AUTOSAR XML (schema 4-0-3)
package /ComponentTypes
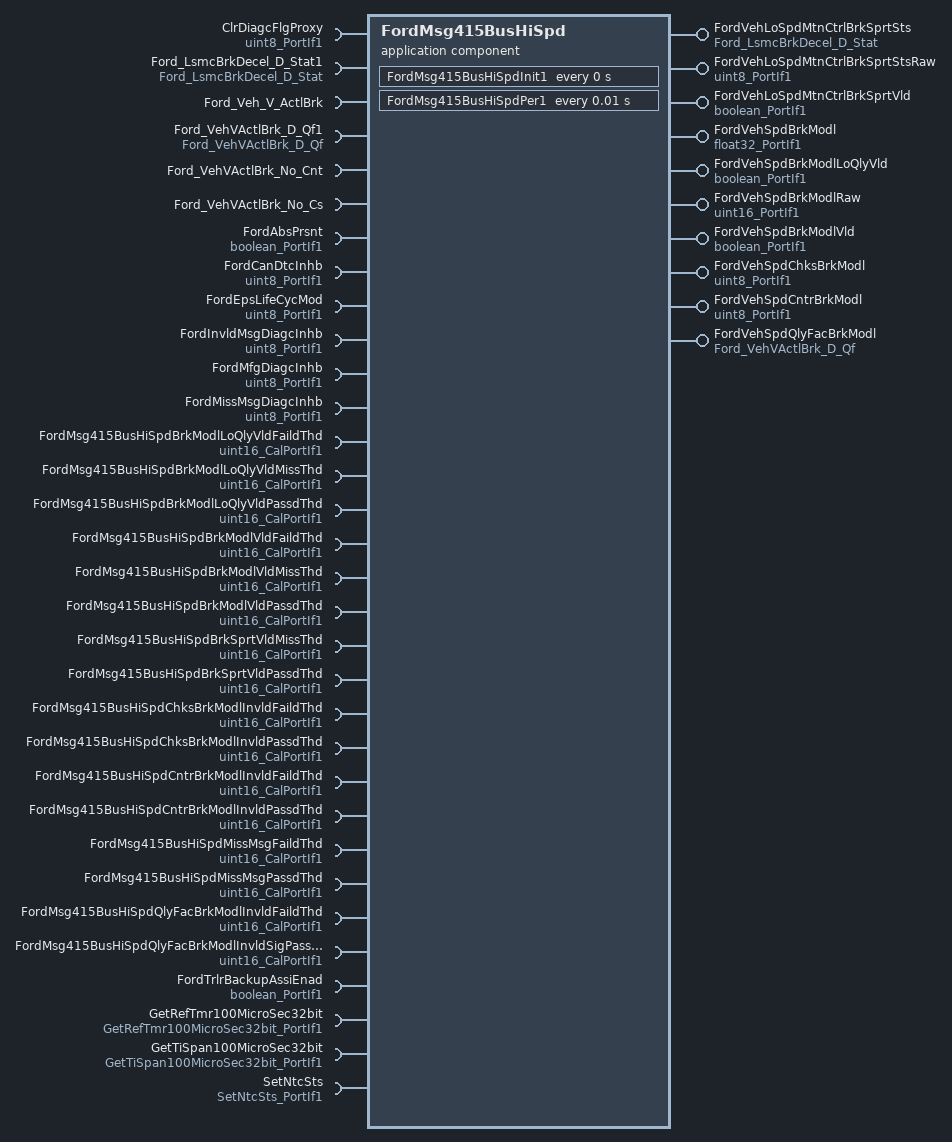
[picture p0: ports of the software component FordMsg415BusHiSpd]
  application sw component type FordMsg415BusHiSpd
    10 x provide port:
      FordVehLoSpdMtnCtrlBrkSprtSts: nonqueued-sender-com-spec{data-element=Ford_LsmcBrkDecel_D_Stat, init-value=0}, provided-interface=Ford_LsmcBrkDecel_D_Stat
      FordVehLoSpdMtnCtrlBrkSprtStsRaw: nonqueued-sender-com-spec{data-element=Val, init-value=0}, provided-interface=uint8_PortIf1
      FordVehLoSpdMtnCtrlBrkSprtVld: nonqueued-sender-com-spec{data-element=Logl, init-value=0}, provided-interface=boolean_PortIf1
      FordVehSpdBrkModl: nonqueued-sender-com-spec{data-element=Val, init-value=0}, provided-interface=float32_PortIf1
      FordVehSpdBrkModlLoQlyVld: nonqueued-sender-com-spec{data-element=Logl, init-value=0}, provided-interface=boolean_PortIf1
      FordVehSpdBrkModlRaw: nonqueued-sender-com-spec{data-element=Val, init-value=0}, provided-interface=uint16_PortIf1
      FordVehSpdBrkModlVld: nonqueued-sender-com-spec{data-element=Logl, init-value=0}, provided-interface=boolean_PortIf1
      FordVehSpdChksBrkModl: nonqueued-sender-com-spec{data-element=Val, init-value=0}, provided-interface=uint8_PortIf1
      FordVehSpdCntrBrkModl: nonqueued-sender-com-spec{data-element=Val, init-value=0}, provided-interface=uint8_PortIf1
      FordVehSpdQlyFacBrkModl: nonqueued-sender-com-spec{data-element=Ford_VehVActlBrk_D_Qf, init-value=0}, provided-interface=Ford_VehVActlBrk_D_Qf
    32 x require port:
      ClrDiagcFlgProxy: nonqueued-receiver-com-spec{data-element=Val, filter=data-filter-type=ALWAYS, init-value=0}, required-interface=uint8_PortIf1
      Ford_LsmcBrkDecel_D_Stat1: nonqueued-receiver-com-spec{data-element=Ford_LsmcBrkDecel_D_Stat, filter=data-filter-type=ALWAYS, init-value=0}, required-interface=Ford_LsmcBrkDecel_D_Stat
      Ford_Veh_V_ActlBrk: nonqueued-receiver-com-spec{data-element=Ford_Veh_V_ActlBrk, filter=data-filter-type=ALWAYS, init-value=0}, required-interface=Ford_Veh_V_ActlBrk
      Ford_VehVActlBrk_D_Qf1: nonqueued-receiver-com-spec{data-element=Ford_VehVActlBrk_D_Qf, filter=data-filter-type=ALWAYS, init-value=0}, required-interface=Ford_VehVActlBrk_D_Qf
      Ford_VehVActlBrk_No_Cnt: nonqueued-receiver-com-spec{data-element=Ford_VehVActlBrk_No_Cnt, filter=data-filter-type=ALWAYS, init-value=0}, required-interface=Ford_VehVActlBrk_No_Cnt
      Ford_VehVActlBrk_No_Cs: nonqueued-receiver-com-spec{data-element=Ford_VehVActlBrk_No_Cs, filter=data-filter-type=ALWAYS, init-value=0}, required-interface=Ford_VehVActlBrk_No_Cs
      FordAbsPrsnt: nonqueued-receiver-com-spec{data-element=Logl, filter=data-filter-type=ALWAYS, init-value=0}, required-interface=boolean_PortIf1
      FordCanDtcInhb: nonqueued-receiver-com-spec{data-element=Val, filter=data-filter-type=ALWAYS, init-value=1}, required-interface=uint8_PortIf1
      FordEpsLifeCycMod: nonqueued-receiver-com-spec{data-element=Val, filter=data-filter-type=ALWAYS, init-value=0}, required-interface=uint8_PortIf1
      FordInvldMsgDiagcInhb: nonqueued-receiver-com-spec{data-element=Val, filter=data-filter-type=ALWAYS, init-value=0}, required-interface=uint8_PortIf1
      FordMfgDiagcInhb: nonqueued-receiver-com-spec{data-element=Val, filter=data-filter-type=ALWAYS, init-value=0}, required-interface=uint8_PortIf1
      FordMissMsgDiagcInhb: nonqueued-receiver-com-spec{data-element=Val, filter=data-filter-type=ALWAYS, init-value=0}, required-interface=uint8_PortIf1
      FordMsg415BusHiSpdBrkModlLoQlyVldFaildThd: parameter-require-com-spec{init-value=0, parameter=Val}, required-interface=uint16_CalPortIf1
      FordMsg415BusHiSpdBrkModlLoQlyVldMissThd: parameter-require-com-spec{init-value=0, parameter=Val}, required-interface=uint16_CalPortIf1
      FordMsg415BusHiSpdBrkModlLoQlyVldPassdThd: parameter-require-com-spec{init-value=0, parameter=Val}, required-interface=uint16_CalPortIf1
      FordMsg415BusHiSpdBrkModlVldFaildThd: parameter-require-com-spec{init-value=0, parameter=Val}, required-interface=uint16_CalPortIf1
      FordMsg415BusHiSpdBrkModlVldMissThd: parameter-require-com-spec{init-value=0, parameter=Val}, required-interface=uint16_CalPortIf1
      FordMsg415BusHiSpdBrkModlVldPassdThd: parameter-require-com-spec{init-value=0, parameter=Val}, required-interface=uint16_CalPortIf1
      FordMsg415BusHiSpdBrkSprtVldMissThd: parameter-require-com-spec{init-value=0, parameter=Val}, required-interface=uint16_CalPortIf1
      FordMsg415BusHiSpdBrkSprtVldPassdThd: parameter-require-com-spec{init-value=0, parameter=Val}, required-interface=uint16_CalPortIf1
      FordMsg415BusHiSpdChksBrkModlInvldFaildThd: parameter-require-com-spec{init-value=0, parameter=Val}, required-interface=uint16_CalPortIf1
      FordMsg415BusHiSpdChksBrkModlInvldPassdThd: parameter-require-com-spec{init-value=0, parameter=Val}, required-interface=uint16_CalPortIf1
      FordMsg415BusHiSpdCntrBrkModlInvldFaildThd: parameter-require-com-spec{init-value=0, parameter=Val}, required-interface=uint16_CalPortIf1
      FordMsg415BusHiSpdCntrBrkModlInvldPassdThd: parameter-require-com-spec{init-value=0, parameter=Val}, required-interface=uint16_CalPortIf1
      FordMsg415BusHiSpdMissMsgFaildThd: parameter-require-com-spec{init-value=100, parameter=Val}, required-interface=uint16_CalPortIf1
      FordMsg415BusHiSpdMissMsgPassdThd: parameter-require-com-spec{init-value=0, parameter=Val}, required-interface=uint16_CalPortIf1
      FordMsg415BusHiSpdQlyFacBrkModlInvldFaildThd: parameter-require-com-spec{init-value=0, parameter=Val}, required-interface=uint16_CalPortIf1
      FordMsg415BusHiSpdQlyFacBrkModlInvldSigPassdThd: parameter-require-com-spec{init-value=0, parameter=Val}, required-interface=uint16_CalPortIf1
      FordTrlrBackupAssiEnad: nonqueued-receiver-com-spec{data-element=Logl, filter=data-filter-type=ALWAYS, init-value=0}, required-interface=boolean_PortIf1
      GetRefTmr100MicroSec32bit: client-com-spec=Oper, required-interface=GetRefTmr100MicroSec32bit_PortIf1
      GetTiSpan100MicroSec32bit: client-com-spec=Oper, required-interface=GetTiSpan100MicroSec32bit_PortIf1
      SetNtcSts: client-com-spec=Oper, required-interface=SetNtcSts_PortIf1
    behavior FordMsg415BusHiSpd_InternalBehavior
      ar-typed-per-instance-memorys:
        31 x data, all with sw-calibration-access=READ-ONLY:
          BrkModlLoQlyVldFaildRefTi: type=uint32
          BrkModlLoQlyVldMissRefTi: type=uint32
          BrkModlLoQlyVldPassdRefTi: type=uint32
          BrkModlVldFaildRefTi: type=uint32
          BrkModlVldMissRefTi: type=uint32
          BrkModlVldPassdRefTi: type=uint32
          BrkSprtVldMissRefTi: type=uint32
          BrkSprtVldPassdRefTi: type=uint32
          ChksBrkModlInvldFaildRefTi: type=uint32
          ChksBrkModlInvldPassdRefTi: type=uint32
          ClrDiagcFlgProxyPrev: type=uint8
          CntrBrkModlInvldFaildRefTi: type=uint32
          CntrBrkModlInvldPassdRefTi: type=uint32
          FirstTranVldFlg: type=boolean
          FordVehLoSpdMtnCtrlBrkSprtStsPrev: type=Ford_LsmcBrkDecel_D_Stat
          FordVehLoSpdMtnCtrlBrkSprtStsRawPrev: type=uint8
          FordVehLoSpdMtnCtrlBrkSprtVldFlg: type=boolean
          FordVehLoSpdMtnCtrlBrkSprtVldPrev: type=boolean
          FordVehMsg415Miss: type=boolean
          FordVehMsg415Rxd: type=boolean
          FordVehSpdBrkModlLoQlyVldPrev: type=boolean
          FordVehSpdBrkModlPrev: type=float32
          FordVehSpdBrkModlRawPrev: type=uint16
          FordVehSpdBrkModlVldPrev: type=boolean
          FordVehSpdChksBrkModlPrev: type=uint8
          FordVehSpdCntrBrkModlPrev: type=uint8
          FordVehSpdQlyFacBrkModlPrev: type=Ford_VehVActlBrk_D_Qf
          MissMsgFaildRefTi: type=uint32
          MissMsgPassdRefTi: type=uint32
          QlyFacBrkModlInvldFaildRefTi: type=uint32
          QlyFacBrkModlInvldPassdRefTi: type=uint32
      timing event FordMsg415BusHiSpd_InitEvent: start-on-event=FordMsg415BusHiSpdInit1, period=0
      timing event TMT_FordMsg415BusHiSpdPer1: start-on-event=FordMsg415BusHiSpdPer1, period=0.01
      port-api-options:
        enable-take-address=false, indirect-api=false, port=Ford_Veh_V_ActlBrk
        enable-take-address=false, indirect-api=false, port=Ford_VehVActlBrk_No_Cnt
        enable-take-address=false, indirect-api=false, port=Ford_VehVActlBrk_No_Cs
        enable-take-address=false, indirect-api=false, port=FordCanDtcInhb
        enable-take-address=false, indirect-api=false, port=FordVehSpdBrkModlLoQlyVld
      runnable FordMsg415BusHiSpdInit1
        sync call SC_GetRefTmr100MicroSec32bit_Oper: operation=GetRefTmr100MicroSec32bit.Oper, timeout=0
      runnable FordMsg415BusHiSpdPer1
        data-receive-point-by-arguments:
          13 x access:
            REC_ClrDiagcFlgProxy_Val: accessed-variable=ClrDiagcFlgProxy.Val
            REC_Ford_LsmcBrkDecel_D_Stat1_Ford_LsmcBrkDecel_D_Stat: accessed-variable=Ford_LsmcBrkDecel_D_Stat1.Ford_LsmcBrkDecel_D_Stat
            REC_Ford_Veh_V_ActlBrk_Ford_Veh_V_ActlBrk: accessed-variable=Ford_Veh_V_ActlBrk.Ford_Veh_V_ActlBrk
            REC_Ford_VehVActlBrk_D_Qf1_Ford_VehVActlBrk_D_Qf: accessed-variable=Ford_VehVActlBrk_D_Qf1.Ford_VehVActlBrk_D_Qf
            REC_Ford_VehVActlBrk_No_Cnt_Ford_VehVActlBrk_No_Cnt: accessed-variable=Ford_VehVActlBrk_No_Cnt.Ford_VehVActlBrk_No_Cnt
            REC_Ford_VehVActlBrk_No_Cs_Ford_VehVActlBrk_No_Cs: accessed-variable=Ford_VehVActlBrk_No_Cs.Ford_VehVActlBrk_No_Cs
            REC_FordAbsPrsnt_Logl: accessed-variable=FordAbsPrsnt.Logl
            REC_FordCanDtcInhb_Val: accessed-variable=FordCanDtcInhb.Val
            REC_FordEpsLifeCycMod_Val: accessed-variable=FordEpsLifeCycMod.Val
            REC_FordInvldMsgDiagcInhb_Val: accessed-variable=FordInvldMsgDiagcInhb.Val
            REC_FordMfgDiagcInhb_Val: accessed-variable=FordMfgDiagcInhb.Val
            REC_FordMissMsgDiagcInhb_Val: accessed-variable=FordMissMsgDiagcInhb.Val
            REC_FordTrlrBackupAssiEnad_Logl: accessed-variable=FordTrlrBackupAssiEnad.Logl
        data-send-points:
          10 x access:
            SEND_FordVehLoSpdMtnCtrlBrkSprtSts_Ford_LsmcBrkDecel_D_Stat: accessed-variable=FordVehLoSpdMtnCtrlBrkSprtSts.Ford_LsmcBrkDecel_D_Stat
            SEND_FordVehLoSpdMtnCtrlBrkSprtStsRaw_Val: accessed-variable=FordVehLoSpdMtnCtrlBrkSprtStsRaw.Val
            SEND_FordVehLoSpdMtnCtrlBrkSprtVld_Logl: accessed-variable=FordVehLoSpdMtnCtrlBrkSprtVld.Logl
            SEND_FordVehSpdBrkModl_Val: accessed-variable=FordVehSpdBrkModl.Val
            SEND_FordVehSpdBrkModlLoQlyVld_Logl: accessed-variable=FordVehSpdBrkModlLoQlyVld.Logl
            SEND_FordVehSpdBrkModlRaw_Val: accessed-variable=FordVehSpdBrkModlRaw.Val
            SEND_FordVehSpdBrkModlVld_Logl: accessed-variable=FordVehSpdBrkModlVld.Logl
            SEND_FordVehSpdChksBrkModl_Val: accessed-variable=FordVehSpdChksBrkModl.Val
            SEND_FordVehSpdCntrBrkModl_Val: accessed-variable=FordVehSpdCntrBrkModl.Val
            SEND_FordVehSpdQlyFacBrkModl_Ford_VehVActlBrk_D_Qf: accessed-variable=FordVehSpdQlyFacBrkModl.Ford_VehVActlBrk_D_Qf
        sync call SC_GetRefTmr100MicroSec32bit_Oper: operation=GetRefTmr100MicroSec32bit.Oper, timeout=0
        sync call SC_GetTiSpan100MicroSec32bit_Oper: operation=GetTiSpan100MicroSec32bit.Oper, timeout=0
        sync call SC_SetNtcSts_Oper: operation=SetNtcSts.Oper, timeout=0
  swc implementation FordMsg415BusHiSpd_Implementation: behavior=FordMsg415BusHiSpd_InternalBehavior
    code-descriptors:
      code Default: artifact-descriptors=autosar-engineering-object={short-label=Default, category=SWSRC}
